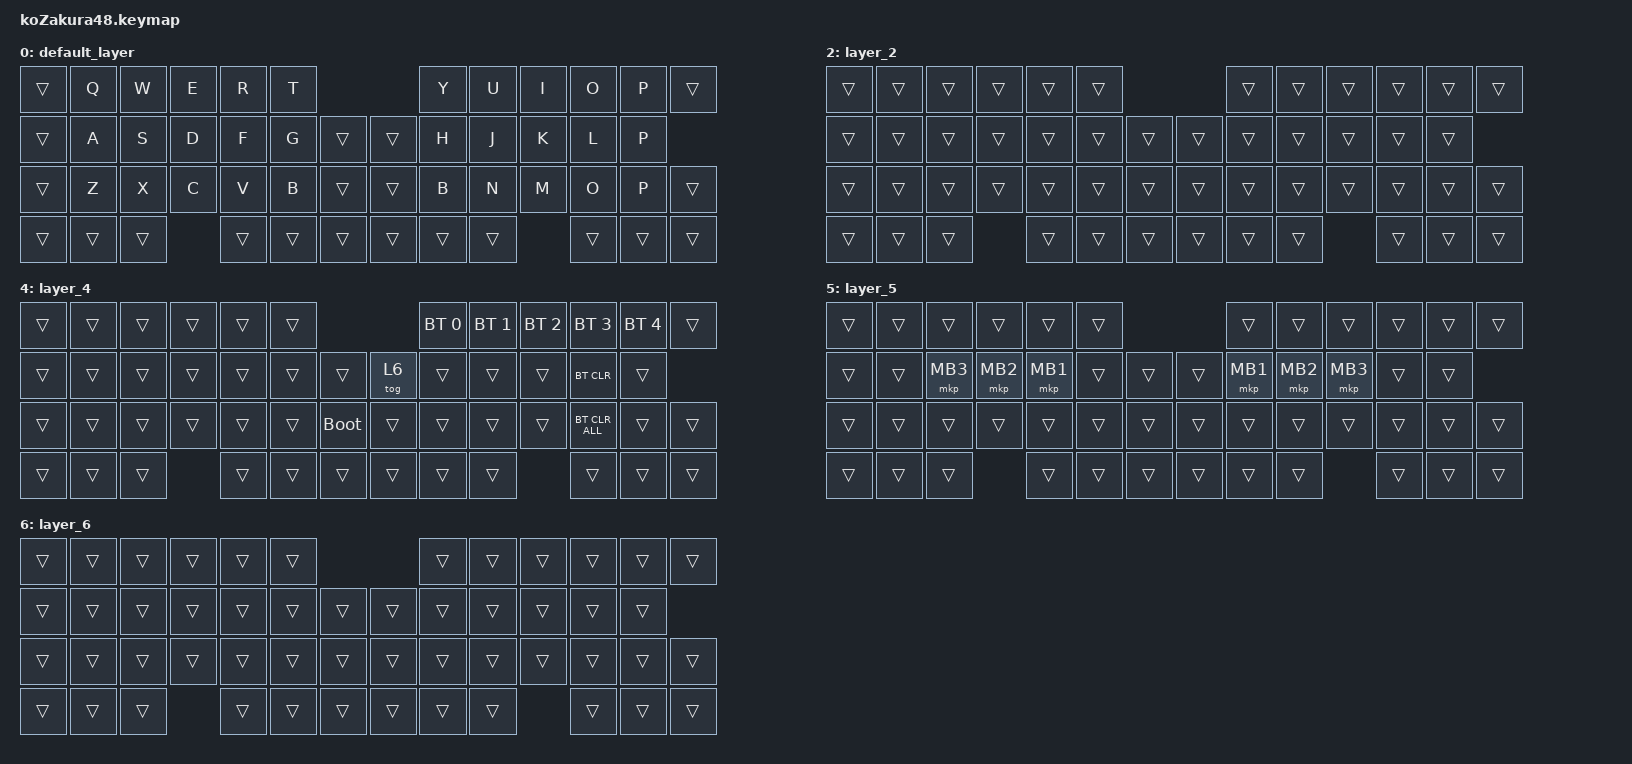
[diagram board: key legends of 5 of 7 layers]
#include <input/processors.dtsi>
#include <dt-bindings/zmk/input_transform.h>
#include <zephyr/dt-bindings/input/input-event-codes.h>
#include <behaviors.dtsi>
#include <dt-bindings/zmk/bt.h>
#include <dt-bindings/zmk/keys.h>
#include <dt-bindings/zmk/pointing.h>

#define ZMK_POINTING_DEFAULT_SCRL_VAL 100
#define MOUSE 5
#define SCROLL 6

&mt {
    flavor = "balanced";
    quick-tap-ms = <0>;
};

/ {
    combos {
        compatible = "zmk,combos";

    //    double_quotation {
    //        bindings = <&kp DOUBLE_QUOTES>;
    //        key-positions = <22 21>;
    //    };

    //    single_quotation {
    //        bindings = <&kp SINGLE_QUOTE>;
    //        key-positions = <21 20>;
    //    };  //よくわからないので一旦コメントアウト
    };

    macros {
        to_layer_0: to_layer_0 {
            compatible = "zmk,behavior-macro-one-param";
            #binding-cells = <1>;
            bindings = <&to 0 &macro_param_1to1 &kp MACRO_PLACEHOLDER>;
            label = "TO_LAYER_0";
        };
    };

    behaviors {
        lt_to_layer_0: lt_to_layer_0 {
            compatible = "zmk,behavior-hold-tap";
            label = "LAYER_TAP_TO_0";
            bindings = <&mo>, <&to_layer_0>;

            #binding-cells = <2>;
            tapping-term-ms = <200>;
        };
    };

    keymap {
        compatible = "zmk,keymap";

        default_layer {
            bindings = <
&trans  &kp Q   &kp  W  &kp E   &kp R   &kp T                     &kp Y   &kp U   &kp I   &kp O   &kp P   &trans
&trans  &kp A   &kp S   &kp D   &kp F   &kp G   &trans    &trans  &kp H   &kp J   &kp K   &kp L   &kp P 
&trans  &kp Z   &kp X   &kp C   &kp V   &kp B   &trans    &trans  &kp B   &kp N   &kp M   &kp O   &kp P   &trans
&trans  &trans  &trans          &trans  &trans  &trans    &trans  &trans  &trans          &trans  &trans  &trans
            >;
        };

        layer_1 {
            bindings = <
&trans  &trans  &trans  &trans  &trans  &trans                    &trans  &trans  &trans  &trans  &trans  &trans
&trans  &trans  &trans  &trans  &trans  &trans  &trans    &trans  &trans  &trans  &trans  &trans  &trans
&trans  &trans  &trans  &trans  &trans  &trans  &trans    &trans  &trans  &trans  &trans  &trans  &trans  &trans
&trans  &trans  &trans          &trans  &trans  &trans    &trans  &trans  &trans          &trans  &trans  &trans                                                     &trans             &trans          &trans        &trans
            >;
        };

        layer_2 {
            bindings = <
&trans  &trans  &trans  &trans  &trans  &trans                    &trans  &trans  &trans  &trans  &trans  &trans
&trans  &trans  &trans  &trans  &trans  &trans  &trans    &trans  &trans  &trans  &trans  &trans  &trans
&trans  &trans  &trans  &trans  &trans  &trans  &trans    &trans  &trans  &trans  &trans  &trans  &trans  &trans
&trans  &trans  &trans          &trans  &trans  &trans    &trans  &trans  &trans          &trans  &trans  &trans
            >;
        };

        layer_3 {
            bindings = <
&trans  &trans          &kp LC(LS(TAB))         &kp PRINTSCREEN      &kp LC(TAB)              &trans                                             &trans  &kp HOME  &kp UP_ARROW     &kp END  &trans  &trans
&trans  &trans          &kp LG(LEFT_ARROW)      &kp LG(RIGHT_ARROW)  &kp LC(LG(LEFT_ARROW))   &kp LC(LG(RIGHT_ARROW))    &trans  &kp LEFT_ARROW  &kp DOWN_ARROW    &kp RIGHT_ARROW  &trans   &trans
&trans  &kp LEFT_SHIFT  &kp LG(LS(LEFT_ARROW))  &trans               &kp LG(LS(RIGHT_ARROW))  &trans                     &trans  &kp DELETE      &kp PAGE_UP       &kp PAGE_DOWN    &trans   &trans  &trans
&trans  &trans          &trans                                       &trans                   &trans                     &trans  &trans          &trans            &trans                    &trans  &trans
            >;
        };

        layer_4 {
            bindings = <
&trans  &trans  &trans  &trans  &trans  &trans                         &bt BT_SEL 0  &bt BT_SEL 1  &bt BT_SEL 2  &bt BT_SEL 3    &bt BT_SEL 4    &trans
&trans  &trans  &trans  &trans  &trans  &trans    &trans       &tog 6  &trans        &trans        &trans        &bt BT_CLR      &trans
&trans  &trans  &trans  &trans  &trans  &trans    &bootloader  &trans  &trans        &trans        &trans        &bt BT_CLR_ALL  &trans          &trans
&trans  &trans  &trans          &trans  &trans    &trans       &trans  &trans        &trans                      &trans          &trans          &trans
            >;
        };

        layer_5 {
            bindings = <
&trans  &trans  &trans    &trans    &trans    &trans                      &trans    &trans    &trans    &trans  &trans  &trans
&trans  &trans  &mkp MB3  &mkp MB2  &mkp MB1  &trans  &trans      &trans  &mkp MB1  &mkp MB2  &mkp MB3  &trans  &trans
&trans  &trans  &trans    &trans    &trans    &trans  &trans      &trans  &trans    &trans    &trans    &trans  &trans  &trans
&trans  &trans  &trans              &trans    &trans  &trans      &trans  &trans    &trans              &trans  &trans  &trans
            >;
        };

        layer_6 {
            bindings = <
&trans  &trans  &trans  &trans  &trans  &trans                    &trans  &trans  &trans  &trans  &trans  &trans
&trans  &trans  &trans  &trans  &trans  &trans  &trans    &trans  &trans  &trans  &trans  &trans  &trans
&trans  &trans  &trans  &trans  &trans  &trans  &trans    &trans  &trans  &trans  &trans  &trans  &trans  &trans
&trans  &trans  &trans          &trans  &trans  &trans    &trans  &trans  &trans          &trans  &trans  &trans
            >;
        };
    };

    // //right hand trackball overrides
    // &trackball_peripheral_listener {
    //     input-processors =
    //         <&zip_xy_transform INPUT_TRANSFORM_XY_SWAP>,//this gets it to the default installation orientation
    //         <&zip_temp_layer 3 500>;//activate layer 3 within 500ms of the trackball moving
    // };
    // //left hand trackball overrides
    // &trackball_central_listener {
    //     input-processors = 
    //         <&zip_xy_transform INPUT_TRANSFORM_XY_SWAP>,//this gets it to the default installation orientation
    //         <&zip_xy_scaler 1 3>,//multiply sensitivity by 1, divide by 3 (make it slower for scrolling)
    //         <&zip_xy_to_scroll_mapper>,//make this trackball output scrolling events by default instead of cursor movement
    //         <&zip_scroll_transform INPUT_TRANSFORM_Y_INVERT>;//invert vertical scrolling so that the view moves in the same direction as the top of the trackball.
    // };
};
